# ESP32-H4 register map
Vendor: ESPRESSIF SYSTEMS (SHANGHAI) CO., LTD.; Series: ESP32 H-Series; File version: 1
CPU: RV32IMAC r0p0, little endian, no MPU, no FPU, 0 interrupt priority bits
Address unit: 32 bits
Registers are 32-bit, read-write, reset 0x0 unless marked. A register's access mark holds for its fields unless they carry their own. Offsets are from the block's base; [hi:lo] are bit positions; {n}, {i} and the like mark numbered series; <NAME> marks a mode.

## I2C0 — I2C (Inter-Integrated Circuit) Controller 0
Base 0x60015000
Same registers: I2C1 0x60016000
0x00 SCL_LOW_PERIOD — Configures the low level width of the SCL Clock
  [8:0] SCL_LOW_PERIOD — Configures the low level width of the SCL Clock in master mode. \\ Measurement unit: i2c_sclk \\
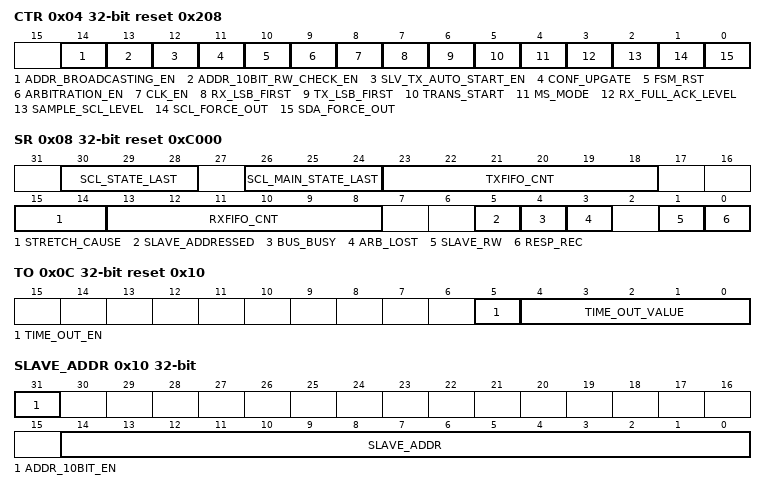
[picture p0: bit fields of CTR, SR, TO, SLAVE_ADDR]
0x04 CTR access per field reset 0x208 — Transmission setting
  [14] ADDR_BROADCASTING_EN rw — Configures to support the 7 bit general call function.\\ 0: Not support \\ 1: Support \\
  [13] ADDR_10BIT_RW_CHECK_EN rw — Configures to check if the r/w bit of 10bit addressing consists with I2C protocol.\\ 0: Not check\\ 1: Check
  [12] SLV_TX_AUTO_START_EN rw — Configures to enable slave to send data automatically\\ 0: Disable\\ 1: Enable \\
  [11] CONF_UPGATE wo — Configures this bit for synchronization.\\ 0: No effect \\ 1: Synchronize
  [10] FSM_RST wo — Configures to reset the SCL_FSM.\\ 0: No effect \\ 1: Reset
  [9] ARBITRATION_EN rw — Configures to enable I2C bus arbitration detection.\\ 0: No effect \\ 1: Enable \\
  [8] CLK_EN rw — Configures whether to gate clock signal for registers.\\ 0: Support clock only when registers are read or written to by software \\ 1: Force clock on for registers \\
  [7] RX_LSB_FIRST rw — Configures to control the storage order for received data.\\ 0: receive data from the most significant bit \\ 1: receive data from the least significant bit \\
  [6] TX_LSB_FIRST rw — Configures to control the sending order for data needing to be sent.\\ 0: send data from the most significant bit \\ 1: send data from the least significant bit \\
  [5] TRANS_START wo — Configures whether the slave starts sending the data in txfifo.\\ 0: No effect \\ 1: Start
  [4] MS_MODE rw — Configures the module as an I2C Master or Slave.\\ 0: Slave \\ 1: Master \\
  [3] RX_FULL_ACK_LEVEL rw — Configures the ACK value that needs to be sent by master when the rx_fifo_cnt has reached the threshold.\\
  [2] SAMPLE_SCL_LEVEL rw — Configures the sample mode for SDA.\\ 0: Sample SDA data on the SCL high level \\ 1: Sample SDA data on the SCL low level \\
  [1] SCL_FORCE_OUT rw — Configures the SCL output mode.\\ 0: Open drain output \\ 1: Direct output \\
  [0] SDA_FORCE_OUT rw — Configures the SDA output mode.\\ 0: Open drain output \\ 1: Direct output \\
0x08 SR ro reset 0xC000 — Describe I2C work status
  [30:28] SCL_STATE_LAST — Represents the states of the state machine used to produce SCL.\\ 0: Idle\\ 1: Start\\ 2: Negative edge\\ 3: Low\\ 4: Positive edge\\ 5: High\\ 6: Stop
  [26:24] SCL_MAIN_STATE_LAST — Represents the states of the I2C module state machine.\\ 0: Idle\\ 1: Address shift\\ 2: ACK address\\ 3: Rx data\\ 4: Tx data\\ 5: Send ACK\\ 6: Wait ACK
  [23:18] TXFIFO_CNT — Represents the number of data bytes to be sent.
  [15:14] STRETCH_CAUSE — Represents the cause of SCL clocking stretching in slave mode.\\ 0: Stretching SCL low when the master starts to read data.\\ 1: Stretching SCL low when I2C TX FIFO is empty in slave mode.\\ 2: Stretching SCL low when I2C RX FIFO is full in slave mode.
  [13:8] RXFIFO_CNT — Represents the number of data bytes received in RAM.
  [5] SLAVE_ADDRESSED — Represents whether the address sent by the master is equal to the address of the slave.\\ Valid only when the module is configured as an I2C Slave.\\ 0: Not equal\\ 1: Equal\\
  [4] BUS_BUSY — Represents the I2C bus state.\\ 1: The I2C bus is busy transferring data\\ 0: The I2C bus is in idle state.\\
  [3] ARB_LOST — Represents whether the I2C controller loses control of SCL line.\\ 0: No arbitration lost\\ 1: Arbitration lost\\
  [1] SLAVE_RW — Represents the transfer direction in slave mode.\\ 1: Master reads from slave\\ 0: Master writes to slave.
  [0] RESP_REC — Represents the received ACK value in master mode or slave mode.\\ 0: ACK\\ 1: NACK.
0x0C TO reset 0x10 — Setting time out control for receiving data
  [5] TIME_OUT_EN — Configures to enable time out control.\\ 0: No effect \\ 1: Enable \\
  [4:0] TIME_OUT_VALUE — Configures the timeout threshold period for SCL stucking at high or low level. The actual period is 2\^{}(reg_time_out_value).\\ Measurement unit: i2c_sclk \\
0x10 SLAVE_ADDR — Local slave address setting
  [31] ADDR_10BIT_EN — Configures to enable the slave 10-bit addressing mode in master mode.\\ 0: No effect \\ 1: Enable \\
  [14:0] SLAVE_ADDR — Configure the slave address of I2C Slave.\\
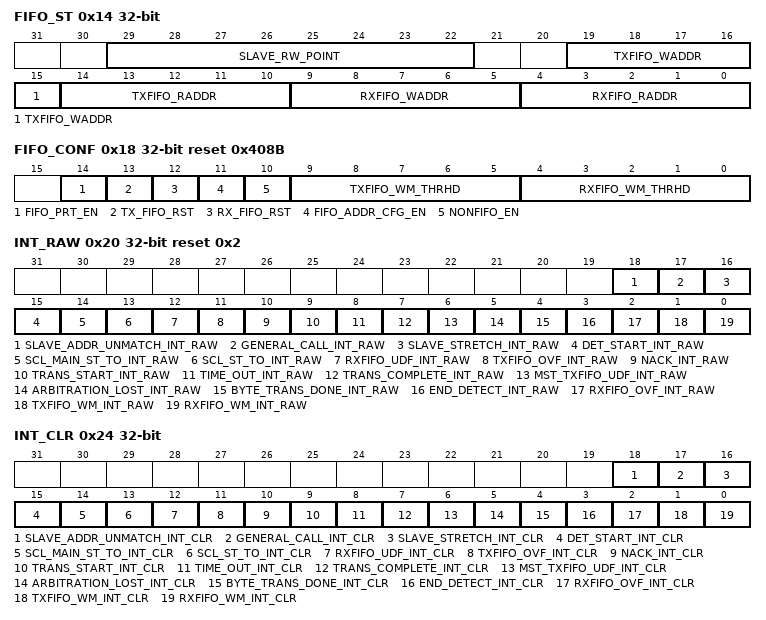
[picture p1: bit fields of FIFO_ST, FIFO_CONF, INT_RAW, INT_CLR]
0x14 FIFO_ST ro — FIFO status register
  [29:22] SLAVE_RW_POINT — Represents the offset address in the I2C Slave RAM addressed by I2C Master when in I2C slave mode.
  [19:15] TXFIFO_WADDR — Represents the offset address of APB bus writing to TXFIFO.
  [14:10] TXFIFO_RADDR — Represents the offset address of i2c module reading from TXFIFO.
  [9:5] RXFIFO_WADDR — Represents the offset address of i2c module receiving data and writing to RXFIFO.
  [4:0] RXFIFO_RADDR — Represents the offset address of the APB reading from RXFIFO.
0x18 FIFO_CONF reset 0x408B — FIFO configuration register
  [14] FIFO_PRT_EN — Configures to enable FIFO pointer in non-fifo access mode. This bit controls the valid bits and the TX/RX FIFO overflow, underflow, full and empty interrupts.\\ 0: No effect \\ 1: Enable \\
  [13] TX_FIFO_RST — Configures to reset TXFIFO.\\ 0: No effect \\ 1: Reset
  [12] RX_FIFO_RST — Configures to reset RXFIFO.\\ 0: No effect \\ 1: Reset
  [11] FIFO_ADDR_CFG_EN — Configures the slave to enable dual address mode. When this mode is enabled, the byte received after the I2C address byte represents the offset address in the I2C Slave RAM. \\ 0: Disable\\ 1: Enable \\
  [10] NONFIFO_EN — Configures to enable APB nonfifo access.
  [9:5] TXFIFO_WM_THRHD — Configures the water mark threshold of TXFIFO in nonfifo access mode. When I2C_FIFO_PRT_EN is 1 and TC FIFO counter is bigger than I2C_TXFIFO_WM_THRHD[4:0], I2C_TXFIFO_WM_INT_RAW bit will be valid.
  [4:0] RXFIFO_WM_THRHD — Configures the water mark threshold of RXFIFO in nonfifo access mode. When I2C_FIFO_PRT_EN is 1 and RX FIFO counter is bigger than I2C_RXFIFO_WM_THRHD[4:0], I2C_RXFIFO_WM_INT_RAW bit will be valid. ododone{For CJ, please check this description. I habe doubt about reg_reg_fifo_prt_en.CJ: modified}
0x1C DATA ro — Rx FIFO read data
  [7:0] FIFO_RDATA — Represents the value of RXFIFO read data.
0x20 INT_RAW ro reset 0x2 — Raw interrupt status
  [18] SLAVE_ADDR_UNMATCH_INT_RAW — The raw interrupt status of I2C_SLAVE_ADDR_UNMATCH_INT_RAW interrupt.
  [17] GENERAL_CALL_INT_RAW — The raw interrupt status of I2C_GENARAL_CALL_INT interrupt.
  [16] SLAVE_STRETCH_INT_RAW — The raw interrupt status of I2C_SLAVE_STRETCH_INT interrupt.
  [15] DET_START_INT_RAW — The raw interrupt status of I2C_DET_START_INT interrupt.
  [14] SCL_MAIN_ST_TO_INT_RAW — The raw interrupt status of I2C_SCL_MAIN_ST_TO_INT interrupt.
  [13] SCL_ST_TO_INT_RAW — The raw interrupt status of I2C_SCL_ST_TO_INT interrupt.
  [12] RXFIFO_UDF_INT_RAW — The raw interrupt status of I2C_RXFIFO_UDF_INT interrupt.
  [11] TXFIFO_OVF_INT_RAW — The raw interrupt status of I2C_TXFIFO_OVF_INT interrupt.
  [10] NACK_INT_RAW — The raw interrupt status of I2C_SLAVE_STRETCH_INT interrupt.
  [9] TRANS_START_INT_RAW — The raw interrupt status of the I2C_TRANS_START_INT interrupt.
  [8] TIME_OUT_INT_RAW — The raw interrupt status of the I2C_TIME_OUT_INT interrupt.
  [7] TRANS_COMPLETE_INT_RAW — The raw interrupt status of the I2C_TRANS_COMPLETE_INT interrupt.
  [6] MST_TXFIFO_UDF_INT_RAW — The raw interrupt status of I2C_TRANS_COMPLETE_INT interrupt.
  [5] ARBITRATION_LOST_INT_RAW — The raw interrupt status of the I2C_ARBITRATION_LOST_INT interrupt.
  [4] BYTE_TRANS_DONE_INT_RAW — The raw interrupt status of the I2C_END_DETECT_INT interrupt.
  [3] END_DETECT_INT_RAW — The raw interrupt status of the I2C_END_DETECT_INT interrupt.
  [2] RXFIFO_OVF_INT_RAW — The raw interrupt status of I2C_RXFIFO_OVF_INT interrupt.
  [1] TXFIFO_WM_INT_RAW — The raw interrupt status of I2C_TXFIFO_WM_INT interrupt.
  [0] RXFIFO_WM_INT_RAW — The raw interrupt status of I2C_RXFIFO_WM_INT interrupt.
0x24 INT_CLR wo — Interrupt clear bits
  [18] SLAVE_ADDR_UNMATCH_INT_CLR — Write 1 to clear I2C_SLAVE_ADDR_UNMATCH_INT_RAW interrupt.
  [17] GENERAL_CALL_INT_CLR — Write 1 to clear I2C_GENARAL_CALL_INT interrupt.
  [16] SLAVE_STRETCH_INT_CLR — Write 1 to clear I2C_SLAVE_STRETCH_INT interrupt.
  [15] DET_START_INT_CLR — Write 1 to clear I2C_DET_START_INT interrupt.
  [14] SCL_MAIN_ST_TO_INT_CLR — Write 1 to clear I2C_SCL_MAIN_ST_TO_INT interrupt.
  [13] SCL_ST_TO_INT_CLR — Write 1 to clear I2C_SCL_ST_TO_INT interrupt.
  [12] RXFIFO_UDF_INT_CLR — Write 1 to clear I2C_RXFIFO_UDF_INT interrupt.
  [11] TXFIFO_OVF_INT_CLR — Write 1 to clear I2C_TXFIFO_OVF_INT interrupt.
  [10] NACK_INT_CLR — Write 1 to clear I2C_SLAVE_STRETCH_INT interrupt.
  [9] TRANS_START_INT_CLR — Write 1 to clear the I2C_TRANS_START_INT interrupt.
  [8] TIME_OUT_INT_CLR — Write 1 to clear the I2C_TIME_OUT_INT interrupt.
  [7] TRANS_COMPLETE_INT_CLR — Write 1 to clear the I2C_TRANS_COMPLETE_INT interrupt.
  [6] MST_TXFIFO_UDF_INT_CLR — Write 1 to clear I2C_TRANS_COMPLETE_INT interrupt.
  [5] ARBITRATION_LOST_INT_CLR — Write 1 to clear the I2C_ARBITRATION_LOST_INT interrupt.
  [4] BYTE_TRANS_DONE_INT_CLR — Write 1 to clear the I2C_END_DETECT_INT interrupt.
  [3] END_DETECT_INT_CLR — Write 1 to clear the I2C_END_DETECT_INT interrupt.
  [2] RXFIFO_OVF_INT_CLR — Write 1 to clear I2C_RXFIFO_OVF_INT interrupt.
  [1] TXFIFO_WM_INT_CLR — Write 1 to clear I2C_TXFIFO_WM_INT interrupt.
  [0] RXFIFO_WM_INT_CLR — Write 1 to clear I2C_RXFIFO_WM_INT interrupt.
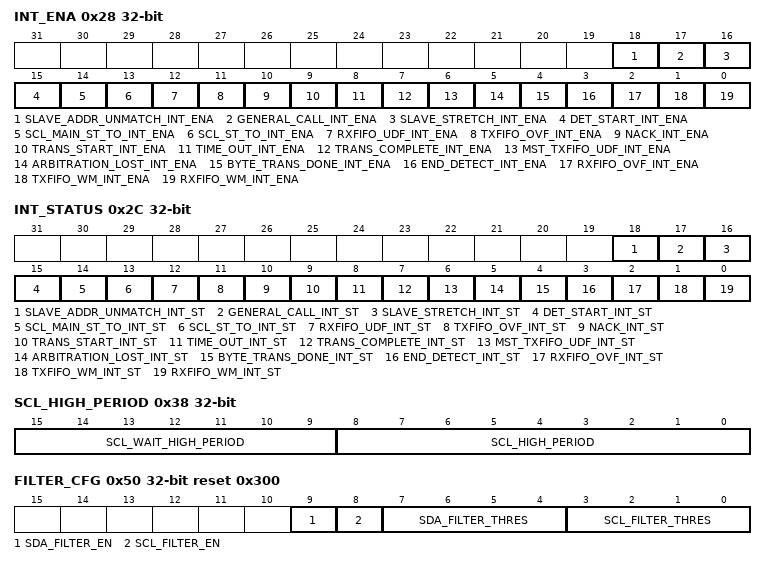
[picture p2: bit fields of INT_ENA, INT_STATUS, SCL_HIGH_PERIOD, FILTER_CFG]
0x28 INT_ENA — Interrupt enable bits
  [18] SLAVE_ADDR_UNMATCH_INT_ENA — Write 1 to enable I2C_SLAVE_ADDR_UNMATCH_INT interrupt.
  [17] GENERAL_CALL_INT_ENA — Write 1 to enable I2C_GENARAL_CALL_INT interrupt.
  [16] SLAVE_STRETCH_INT_ENA — Write 1 to enable I2C_SLAVE_STRETCH_INT interrupt.
  [15] DET_START_INT_ENA — Write 1 to enable I2C_DET_START_INT interrupt.
  [14] SCL_MAIN_ST_TO_INT_ENA — Write 1 to enable I2C_SCL_MAIN_ST_TO_INT interrupt.
  [13] SCL_ST_TO_INT_ENA — Write 1 to enable I2C_SCL_ST_TO_INT interrupt.
  [12] RXFIFO_UDF_INT_ENA — Write 1 to enable I2C_RXFIFO_UDF_INT interrupt.
  [11] TXFIFO_OVF_INT_ENA — Write 1 to enable I2C_TXFIFO_OVF_INT interrupt.
  [10] NACK_INT_ENA — Write 1 to enable I2C_SLAVE_STRETCH_INT interrupt.
  [9] TRANS_START_INT_ENA — Write 1 to enable the I2C_TRANS_START_INT interrupt.
  [8] TIME_OUT_INT_ENA — Write 1 to enable the I2C_TIME_OUT_INT interrupt.
  [7] TRANS_COMPLETE_INT_ENA — Write 1 to enable the I2C_TRANS_COMPLETE_INT interrupt.
  [6] MST_TXFIFO_UDF_INT_ENA — Write 1 to enable I2C_TRANS_COMPLETE_INT interrupt.
  [5] ARBITRATION_LOST_INT_ENA — Write 1 to enable the I2C_ARBITRATION_LOST_INT interrupt.
  [4] BYTE_TRANS_DONE_INT_ENA — Write 1 to enable the I2C_END_DETECT_INT interrupt.
  [3] END_DETECT_INT_ENA — Write 1 to enable the I2C_END_DETECT_INT interrupt.
  [2] RXFIFO_OVF_INT_ENA — Write 1 to enable I2C_RXFIFO_OVF_INT interrupt.
  [1] TXFIFO_WM_INT_ENA — Write 1 to enable I2C_TXFIFO_WM_INT interrupt.
  [0] RXFIFO_WM_INT_ENA — Write 1 to enable I2C_RXFIFO_WM_INT interrupt.
0x2C INT_STATUS ro — Status of captured I2C communication events
  [18] SLAVE_ADDR_UNMATCH_INT_ST — The masked interrupt status status of I2C_SLAVE_ADDR_UNMATCH_INT interrupt.
  [17] GENERAL_CALL_INT_ST — The masked interrupt status status of I2C_GENARAL_CALL_INT interrupt.
  [16] SLAVE_STRETCH_INT_ST — The masked interrupt status status of I2C_SLAVE_STRETCH_INT interrupt.
  [15] DET_START_INT_ST — The masked interrupt status status of I2C_DET_START_INT interrupt.
  [14] SCL_MAIN_ST_TO_INT_ST — The masked interrupt status status of I2C_SCL_MAIN_ST_TO_INT interrupt.
  [13] SCL_ST_TO_INT_ST — The masked interrupt status status of I2C_SCL_ST_TO_INT interrupt.
  [12] RXFIFO_UDF_INT_ST — The masked interrupt status status of I2C_RXFIFO_UDF_INT interrupt.
  [11] TXFIFO_OVF_INT_ST — The masked interrupt status status of I2C_TXFIFO_OVF_INT interrupt.
  [10] NACK_INT_ST — The masked interrupt status status of I2C_SLAVE_STRETCH_INT interrupt.
  [9] TRANS_START_INT_ST — The masked interrupt status status of the I2C_TRANS_START_INT interrupt.
  [8] TIME_OUT_INT_ST — The masked interrupt status status of the I2C_TIME_OUT_INT interrupt.
  [7] TRANS_COMPLETE_INT_ST — The masked interrupt status status of the I2C_TRANS_COMPLETE_INT interrupt.
  [6] MST_TXFIFO_UDF_INT_ST — The masked interrupt status status of I2C_TRANS_COMPLETE_INT interrupt.
  [5] ARBITRATION_LOST_INT_ST — The masked interrupt status status of the I2C_ARBITRATION_LOST_INT interrupt.
  [4] BYTE_TRANS_DONE_INT_ST — The masked interrupt status status of the I2C_END_DETECT_INT interrupt.
  [3] END_DETECT_INT_ST — The masked interrupt status status of the I2C_END_DETECT_INT interrupt.
  [2] RXFIFO_OVF_INT_ST — The masked interrupt status status of I2C_RXFIFO_OVF_INT interrupt.
  [1] TXFIFO_WM_INT_ST — The masked interrupt status status of I2C_TXFIFO_WM_INT interrupt.
  [0] RXFIFO_WM_INT_ST — The masked interrupt status status of I2C_RXFIFO_WM_INT interrupt.
0x30 SDA_HOLD — Configures the hold time after a negative SCL edge
  [8:0] TIME — Configures the time to hold the data after the falling edge of SCL.\\ Measurement unit: i2c_sclk \\
0x34 SDA_SAMPLE — Configures the sample time after a positive SCL edge
  [8:0] TIME — Configures the time for sampling SDA.\\ Measurement unit: i2c_sclk \\
0x38 SCL_HIGH_PERIOD — Configures the high level width of SCL
  [15:9] SCL_WAIT_HIGH_PERIOD — Configures the SCL_FSM's waiting period for SCL high level in master mode.\\ Measurement unit: i2c_sclk \\
  [8:0] SCL_HIGH_PERIOD — Configures for how long SCL remains high in master mode.\\ Measurement unit: i2c_sclk \\
0x40 SCL_START_HOLD reset 0x8 — Configures the delay between the SDA and SCL negative edge for a start condition
  [8:0] TIME — Configures the time between the falling edge of SDA and the falling edge of SCL for a START condition.\\ Measurement unit: i2c_sclk \\
0x44 SCL_RSTART_SETUP reset 0x8 — Configures the delay between the positive edge of SCL and the negative edge of SDA
  [8:0] TIME — Configures the time between the positive edge of SCL and the negative edge of SDA for a RESTART condition.\\ Measurement unit: i2c_sclk \\
0x48 SCL_STOP_HOLD reset 0x8 — Configures the delay after the SCL clock edge for a stop condition
  [8:0] TIME — Configures the delay after the STOP condition.\\ Measurement unit: i2c_sclk \\
0x4C SCL_STOP_SETUP reset 0x8 — Configures the delay between the SDA and SCL positive edge for a stop condition
  [8:0] TIME — This register is used to configure the time between the positive edgeof SCL and the positive edge of SDA, in I2C module clock cycles.
0x50 FILTER_CFG reset 0x300 — SCL and SDA filter configuration register
  [9] SDA_FILTER_EN — Configures to enable the filter function for SDA. \\ 0: No effect \\ 1: Enable \\
  [8] SCL_FILTER_EN — Configures to enable the filter function for SCL. \\ 0: No effect \\ 1: Enable \\
  [7:4] SDA_FILTER_THRES — Configures the threshold pulse width to be filtered on SDA. When a pulse on the SDA input has smaller width than this register value, the I2C controller will ignore that pulse. Measurement unit: i2c_sclk \\
  [3:0] SCL_FILTER_THRES — Configures the threshold pulse width to be filtered on SCL. When a pulse on the SCL input has smaller width than this register value, the I2C controller will ignore that pulse. Measurement unit: i2c_sclk \\
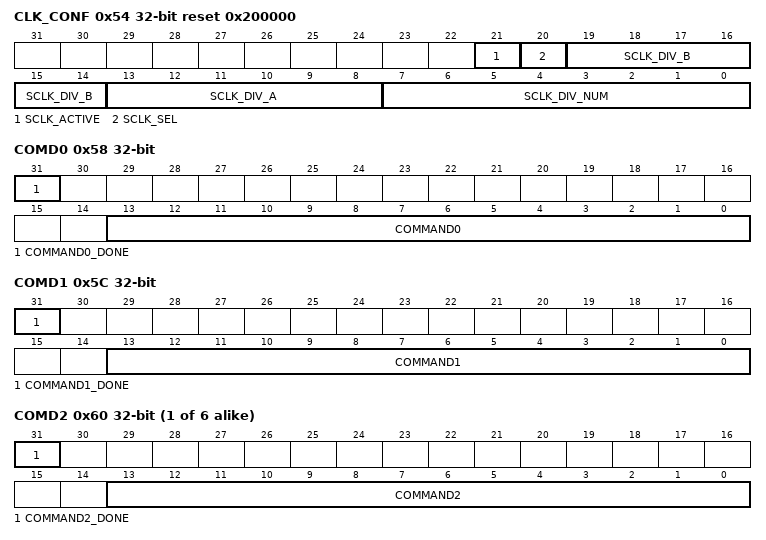
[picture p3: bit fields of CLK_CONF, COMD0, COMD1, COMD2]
0x54 CLK_CONF reset 0x200000 — I2C CLK configuration register
  [21] SCLK_ACTIVE — The clock switch for i2c module
  [20] SCLK_SEL — The clock selection for i2c module:0-XTAL,1-CLK_8MHz.
  [19:14] SCLK_DIV_B — the denominator of the fractional part of the fractional divisor for i2c module
  [13:8] SCLK_DIV_A — the numerator of the fractional part of the fractional divisor for i2c module
  [7:0] SCLK_DIV_NUM — the integral part of the fractional divisor for i2c module
0x58 COMD0 — I2C command register 0
  [31] COMMAND0_DONE — Represents whether command 0 is done in I2C Master mode.\\ 0: Not done \\ 1: Done \\
  [13:0] COMMAND0 — Configures command 0. \\ It consists of three parts:\\ op_code is the command\\ 1: WRITE\\ 2: STOP\\ 3: READ\\ 4: END\\ 6: RSTART\\ Byte_num represents the number of bytes that need to be sent or received.\\ ack_check_en, ack_exp and ack are used to control the ACK bit. See I2C cmd structure <a href=fig:i2c-cmd-structure">link</a> for more information. \\ ododone{for CJ, please add a hyperlink for I2C CMD structure.CJ: done.}"
0x5C COMD1 — I2C command register 1
  [31] COMMAND1_DONE — Represents whether command 1 is done in I2C Master mode.\\ 0: Not done \\ 1: Done \\
  [13:0] COMMAND1 — Configures command 1.\\ See details in I2C_CMD0_REG[13:0].
{0x58+4i} COMD{i} (i=2..7) — I2C command register {i}
  [31] COMMAND{i}_DONE — Represents whether command {i} is done in I2C Master mode.\\ 0: Not done \\ 1: Done \\
  [13:0] COMMAND{i} — Configures command {i}. See details in I2C_CMD0_REG[13:0].
0x78 SCL_ST_TIME_OUT reset 0x10 — SCL status time out register
  [4:0] SCL_ST_TO_I2C — Configures the threshold value of SCL_FSM state unchanged period. It should be no more than 23.\\ Measurement unit: i2c_sclk \\
0x7C SCL_MAIN_ST_TIME_OUT reset 0x10 — SCL main status time out register
  [4:0] SCL_MAIN_ST_TO_I2C — Configures the threshold value of SCL_MAIN_FSM state unchanged period. It should be no more than 23.\\ Measurement unit: i2c_sclk \\
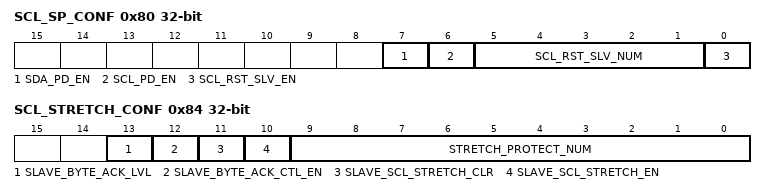
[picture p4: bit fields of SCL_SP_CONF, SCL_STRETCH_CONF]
0x80 SCL_SP_CONF — Power configuration register
  [7] SDA_PD_EN — Configures to power down the I2C output SDA line. \\ 0: Not power down.\\ 1: Not work and power down.\\ Valid only when I2C_SDA_FORCE_OUT is 1.
  [6] SCL_PD_EN — Configures to power down the I2C output SCL line. \\ 0: Not power down.\\ 1: Not work and power down.\\ Valid only when I2C_SCL_FORCE_OUT is 1.
  [5:1] SCL_RST_SLV_NUM — Configure the pulses of SCL generated in I2C master mode. \\ Valid when I2C_SCL_RST_SLV_EN is 1.\\ Measurement unit: i2c_sclk \\
  [0] SCL_RST_SLV_EN — Configures to send out SCL pulses when I2C master is IDLE. The number of pulses equals to I2C_SCL_RST_SLV_NUM[4:0].
0x84 SCL_STRETCH_CONF access per field — Set SCL stretch of I2C slave
  [13] SLAVE_BYTE_ACK_LVL rw — Set the ACK level when slave controlling ACK level function enables.\\ 0: Low level\\ 1: High level \\
  [12] SLAVE_BYTE_ACK_CTL_EN rw — Configures to enable the function for slave to control ACK level.\\ 0: Disable \\ 1: Enable \\
  [11] SLAVE_SCL_STRETCH_CLR wo — Configures to clear the I2C slave SCL stretch function.\\ 0: No effect \\ 1: Clear\\
  [10] SLAVE_SCL_STRETCH_EN rw — Configures to enable slave SCL stretch function. The SCL output line will be stretched low when I2C_SLAVE_SCL_STRETCH_EN is 1 and stretch event happens. The stretch cause can be seen in I2C_STRETCH_CAUSE.\\ 0: Disable \\ 1: Enable \\
  [9:0] STRETCH_PROTECT_NUM rw — Configures the time period to release the SCL line from stretching to avoid timing violation. Usually it should be larger than the SDA setup time.\\ Measurement unit: i2c_sclk \\
0xF8 DATE reset 0x2404080 — Version register
  [31:0] DATE — Version control register.
0x100 TXFIFO_START_ADDR ro — I2C TXFIFO base address register
  [31:0] TXFIFO_START_ADDR — Represents the I2C txfifo first address.
0x180 RXFIFO_START_ADDR ro — I2C RXFIFO base address register
  [31:0] RXFIFO_START_ADDR — Represents the I2C rxfifo first address.
